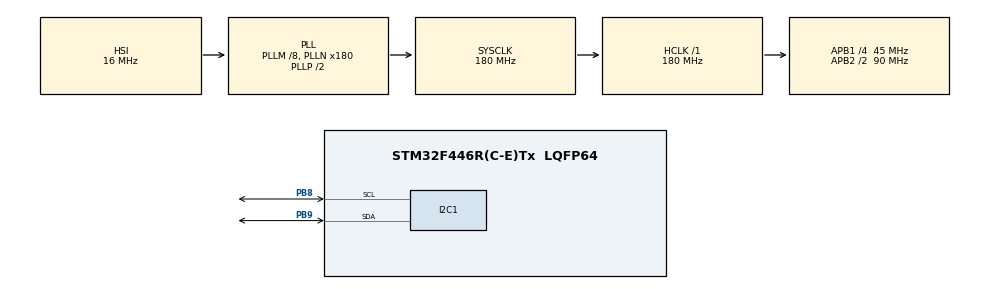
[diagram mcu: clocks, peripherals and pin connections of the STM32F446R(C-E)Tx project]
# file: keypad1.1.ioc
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I2C1.OwnAddress=0x00
Mcu.Family=STM32F4
Mcu.Name=STM32F446R(C-E)Tx
Mcu.Package=LQFP64
NVIC.PriorityGroup=NVIC_PRIORITYGROUP_0
PB8.GPIO_Pu=GPIO_PULLUP
PB8.GPIO_Speed=GPIO_SPEED_FREQ_LOW
PB8.Mode=I2C
PB8.Signal=I2C1_SCL
PB9.GPIO_Pu=GPIO_PULLUP
PB9.GPIO_Speed=GPIO_SPEED_FREQ_LOW
PB9.Mode=I2C
PB9.Signal=I2C1_SDA
PH0-OSC_IN.Mode=HSE-External-Oscillator
PH0-OSC_IN.Signal=RCC_OSC_IN
PH1-OSC_OUT.Mode=HSE-External-Oscillator
PH1-OSC_OUT.Signal=RCC_OSC_OUT
ProjectManager.HeapSize=0x200
ProjectManager.StackSize=0x400
ProjectManager.TargetToolchain=STM32CubeIDE
RCC.48MHZClocksFreq_Value=84000000
RCC.AHBFreq_Value=180000000
RCC.APB1CLKDivider=RCC_HCLK_DIV4
RCC.APB1Freq_Value=45000000
RCC.APB1TimFreq_Value=90000000
RCC.APB2CLKDivider=RCC_HCLK_DIV2
RCC.APB2Freq_Value=90000000
RCC.APB2TimFreq_Value=180000000
RCC.CortexFreq_Value=180000000
RCC.FLatency-AdvancedSettings=FLASH_LATENCY_5
RCC.HCLKFreq_Value=180000000
RCC.HSE_VALUE=8000000
RCC.HSI_VALUE=16000000
RCC.PLLM=8
RCC.PLLN=180
RCC.SYSCLKFreq_VALUE=180000000
RCC.SYSCLKSource=RCC_SYSCLKSOURCE_PLLCLK
RCC.USBFreq_Value=180000000
RCC.VCOOutputFreq_Value=360000000
board=NUCLEO-F446RE

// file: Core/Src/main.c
/* USER CODE BEGIN Header */
/**
  ******************************************************************************
  * @file           : main.c
  * @brief          : Main program body
  ******************************************************************************
  * @attention
  *
  * Copyright (c) 2025 STMicroelectronics.
  * All rights reserved.
  *
  * This software is licensed under terms that can be found in the LICENSE file
  * in the root directory of this software component.
  * If no LICENSE file comes with this software, it is provided AS-IS.
  *
  ******************************************************************************
  */
/* USER CODE END Header */
#include "main.h"

/* USER CODE BEGIN Includes */
#include <stdio.h>

/* USER CODE END Includes */

/* USER CODE BEGIN PM */
#define TTP229_SCL_PIN GPIO_PIN_8
#define TTP229_SCL_PORT GPIOB
#define TTP229_SDO_PIN GPIO_PIN_9
#define TTP229_SDO_PORT GPIOB

/* USER CODE END PM */

I2C_HandleTypeDef hi2c1;

void SystemClock_Config(void);
static void MX_GPIO_Init(void);
static void MX_I2C1_Init(void);

/* USER CODE BEGIN 0 */
const uint16_t TTP229_KEYS[16] = {
		0x0001, 0x0002, 0x0004, 0x0008,
		0x0010, 0x0020, 0x0040, 0x0080,
		0x0100, 0x0200, 0x0400, 0x0800,
		0x1000, 0x2000, 0x4000, 0x8000
};

const char* KEY_LABELS[16] = {
		"1", "2", "3", "A",
		"4", "5", "6", "B",
		"7", "8", "9", "C",
		"*", "0", "#", "D"
};

void TTP229_Delay(void){
	volatile uint32_t delay = 10;
	while(delay--);
}

void TTP229_Start(void){
	HAL_GPIO_WritePin(TTP229_SCL_PORT, TTP229_SCL_PIN, GPIO_PIN_RESET);
	TTP229_Delay();
	HAL_GPIO_WritePin(TTP229_SCL_PORT, TTP229_SCL_PIN, GPIO_PIN_SET);
	TTP229_Delay();
	HAL_GPIO_WritePin(TTP229_SCL_PORT, TTP229_SCL_PIN, GPIO_PIN_RESET);
	TTP229_Delay();
}

uint16_t TTP229_ReadData(void) {
    uint16_t data = 0;

    TTP229_Start();

    // Read 16 bits of data
    for(uint8_t i = 0; i < 16; i++) {
        HAL_GPIO_WritePin(TTP229_SCL_PORT, TTP229_SCL_PIN, GPIO_PIN_SET);
        TTP229_Delay();

        // Read data bit
        if(HAL_GPIO_ReadPin(TTP229_SDO_PORT, TTP229_SDO_PIN)) {
            data |= (1 << (15 - i));
        }

        HAL_GPIO_WritePin(TTP229_SCL_PORT, TTP229_SCL_PIN, GPIO_PIN_RESET);
        TTP229_Delay();
    }

    return data;
}

int8_t TTP229_GetKeyPressed(uint16_t data) {
    if(data == 0) return -1; // No key pressed

    for(uint8_t i = 0; i < 16; i++) {
        if(data & TTP229_KEYS[i]) {
            return i;
        }
    }

    return -1; // No valid key found
}
uint16_t keyData;
int8_t keyIndex;

//void PrintKeyPressed(uint8_t keyIndex) {
//    char buffer[50];
//    int len = sprintf(buffer, "Key Pressed: %s (Index: %d)\r\n",
//                     KEY_LABELS[keyIndex], keyIndex);
//    HAL_UART_Transmit(&huart2, (uint8_t*)buffer, len, HAL_MAX_DELAY);
//}
/* USER CODE END 0 */

int main(void)
{

  /* MCU Configuration--------------------------------------------------------*/

  /* Reset of all peripherals, Initializes the Flash interface and the Systick. */
  HAL_Init();

  /* Configure the system clock */
  SystemClock_Config();

  /* Initialize all configured peripherals */
  MX_GPIO_Init();
  MX_I2C1_Init();
  /* USER CODE BEGIN 2 */
//  uint16_t lastKeyData = 0;
//  uint32_t lastPressTime = 0;

  /* USER CODE END 2 */

  /* Infinite loop */
  while (1)
  {

    /* USER CODE BEGIN 3 */
	  keyData = TTP229_ReadData();
	  keyIndex = TTP229_GetKeyPressed(keyData);

  }
  /* USER CODE END 3 */
}

void SystemClock_Config(void)
{
  RCC_OscInitTypeDef RCC_OscInitStruct = {0};
  RCC_ClkInitTypeDef RCC_ClkInitStruct = {0};

  /** Configure the main internal regulator output voltage
  */
  __HAL_RCC_PWR_CLK_ENABLE();
  __HAL_PWR_VOLTAGESCALING_CONFIG(PWR_REGULATOR_VOLTAGE_SCALE1);

  /** Initializes the RCC Oscillators according to the specified parameters
  * in the RCC_OscInitTypeDef structure.
  */
  RCC_OscInitStruct.OscillatorType = RCC_OSCILLATORTYPE_HSI;
  RCC_OscInitStruct.HSIState = RCC_HSI_ON;
  RCC_OscInitStruct.HSICalibrationValue = RCC_HSICALIBRATION_DEFAULT;
  RCC_OscInitStruct.PLL.PLLState = RCC_PLL_ON;
  RCC_OscInitStruct.PLL.PLLSource = RCC_PLLSOURCE_HSI;
  RCC_OscInitStruct.PLL.PLLM = 8;
  RCC_OscInitStruct.PLL.PLLN = 180;
  RCC_OscInitStruct.PLL.PLLP = RCC_PLLP_DIV2;
  RCC_OscInitStruct.PLL.PLLQ = 2;
  RCC_OscInitStruct.PLL.PLLR = 2;
  if (HAL_RCC_OscConfig(&RCC_OscInitStruct) != HAL_OK)
  {
    Error_Handler();
  }

  /** Activate the Over-Drive mode
  */
  if (HAL_PWREx_EnableOverDrive() != HAL_OK)
  {
    Error_Handler();
  }

  /** Initializes the CPU, AHB and APB buses clocks
  */
  RCC_ClkInitStruct.ClockType = RCC_CLOCKTYPE_HCLK|RCC_CLOCKTYPE_SYSCLK
                              |RCC_CLOCKTYPE_PCLK1|RCC_CLOCKTYPE_PCLK2;
  RCC_ClkInitStruct.SYSCLKSource = RCC_SYSCLKSOURCE_PLLCLK;
  RCC_ClkInitStruct.AHBCLKDivider = RCC_SYSCLK_DIV1;
  RCC_ClkInitStruct.APB1CLKDivider = RCC_HCLK_DIV4;
  RCC_ClkInitStruct.APB2CLKDivider = RCC_HCLK_DIV2;

  if (HAL_RCC_ClockConfig(&RCC_ClkInitStruct, FLASH_LATENCY_5) != HAL_OK)
  {
    Error_Handler();
  }
}

static void MX_I2C1_Init(void)
{

  hi2c1.Instance = I2C1;
  hi2c1.Init.ClockSpeed = 100000;
  hi2c1.Init.DutyCycle = I2C_DUTYCYCLE_2;
  hi2c1.Init.OwnAddress1 = 0;
  hi2c1.Init.AddressingMode = I2C_ADDRESSINGMODE_7BIT;
  hi2c1.Init.DualAddressMode = I2C_DUALADDRESS_DISABLE;
  hi2c1.Init.OwnAddress2 = 0;
  hi2c1.Init.GeneralCallMode = I2C_GENERALCALL_DISABLE;
  hi2c1.Init.NoStretchMode = I2C_NOSTRETCH_DISABLE;
  if (HAL_I2C_Init(&hi2c1) != HAL_OK)
  {
    Error_Handler();
  }

}

static void MX_GPIO_Init(void)
{

  /* GPIO Ports Clock Enable */
  __HAL_RCC_GPIOH_CLK_ENABLE();
  __HAL_RCC_GPIOB_CLK_ENABLE();

}

void Error_Handler(void)
{
  __disable_irq();
  while (1)
  {
  }
}
